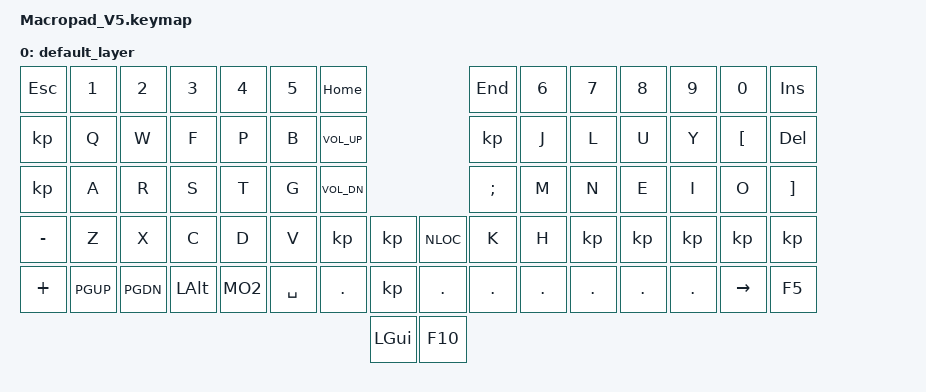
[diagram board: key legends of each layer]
#include <behaviors.dtsi>
#include <dt-bindings/zmk/keys.h>
#include <dt-bindings/zmk/bt.h>

/ {
    keymap {
        compatible = "zmk,keymap";

        default_layer {
// ---------------------------------------------------------------------------------------------------------------------------------
// | ESC  |  1  |  2  |  3  |  4  |  5  |  6  |  7  |   |  8  |  9  |  0  |  -  |  =  | BKSP | HOME | PGUP |
// | TAB  |  Q  |  W  |  E  |  R  |  T  |  Y  |  U  |   |  I  |  O  |  P  |  [  |  ]  |  \   | END  | PGDN |
// | CAPS |  A  |  S  |  D  |  F  |  G  |  H  |  J  |   |  K  |  L  |  ;  |  '  | ENTER      | VOL+ | MUTE |
// | SHFT |  Z  |  X  |  C  |  V  |  B  |  N  |  M  |   |  ,  |  .  |  /  | SHFT|  UP | VOL- | PLAY | STOP |
// | CTRL | GUI | ALT | SPC | SPC | SPC | SPC | SPC |   | SPC | SPC | SPC | SPC | LFT | DWN  | RGHT | F5   |
// | F1   | F2  | F3  | F4  | F6  | F7  | F8  | F9  |   | F10 | F11 | F12 | BT1 | BT2 | BT3  | BT4  | BTCLR|
            bindings = <
    &kp ESC   &kp N1   &kp N2   &kp N3   &kp N4   &kp N5   &kp HOME                  &kp END  &kp N6   &kp N7   &kp N8    &kp N9    &kp N0    &kp INSERT
    &kp       &kp Q    &kp W    &kp F    &kp P    &kp B    &kp C_VOL_UP              &kp      &kp J    &kp L    &kp U     &kp Y     &kp LBKT  &kp DEL
    &kp       &kp A    &kp R    &kp S    &kp T    &kp G    &kp C_VOL_DN              &kp SEMI &kp M    &kp N    &kp E     &kp I     &kp O     &kp RBKT
    &kp MINUS &kp Z    &kp X    &kp C    &kp D    &kp V    &kp     &kp      &kp NLOC &kp K    &kp H    &kp       &kp       &kp       &kp    &kp
    &kp PLUS  &kp PGUP &kp PGDN &kp LALT &kp MO2  &kp SPACE &kp DOT &kp         &kp DOT &kp DOT &kp DOT &kp DOT &kp DOT  &kp DOT  &kp RIGHT &kp F5
                                                                    &kp LGUI    &kp F10
            >;
        };
    };
};
